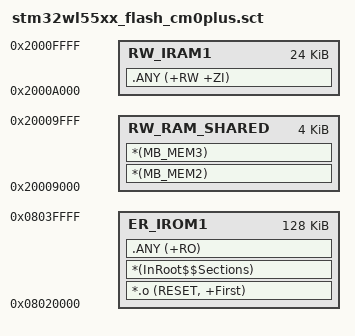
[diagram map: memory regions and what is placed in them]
; *************************************************************
; *** Scatter-Loading Description File generated by uVision ***
; *************************************************************

LR_IROM1 0x08020000 0x00020000  {    ; load region size_region
  ; FLASH part dedicated to M0+
  ER_IROM1 0x08020000 0x00020000  {  ; load address = execution address
   *.o (RESET, +First)
   *(InRoot$$Sections)
   .ANY (+RO)
  }
  ; SRAM2 dedicated to M0+
  RW_IRAM1 0x2000A000 0x00006000  {  ; RW data
   .ANY (+RW +ZI)
  }

  RW_RAM_SHARED 0x20009000 0x1000  {
   *(MB_MEM2)
   *(MB_MEM3)
  }
}
